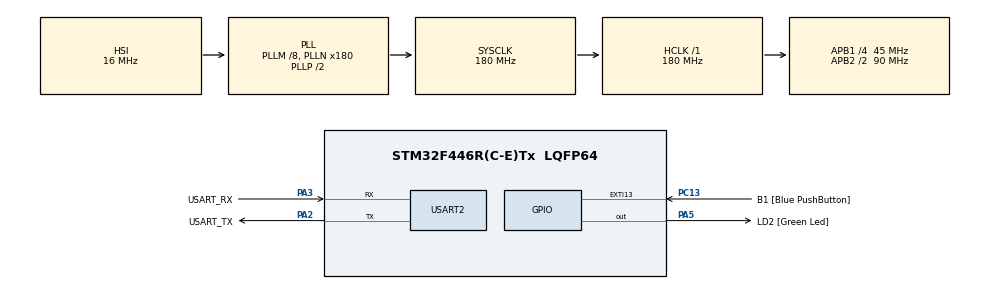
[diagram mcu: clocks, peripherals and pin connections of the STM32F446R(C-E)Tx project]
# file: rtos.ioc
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FREERTOS.Tasks01=defaultTask,24,128,StartDefaultTask,Default,NULL,Dynamic,NULL,NULL
FREERTOS.configUSE_NEWLIB_REENTRANT=0
Mcu.Family=STM32F4
Mcu.Name=STM32F446R(C-E)Tx
Mcu.Package=LQFP64
NVIC.PriorityGroup=NVIC_PRIORITYGROUP_4
NVIC.TIM6_DAC_IRQn=true\:15\:0\:false\:false\:true\:false\:false\:true\:true
NVIC.TimeBase=TIM6_DAC_IRQn
NVIC.TimeBaseIP=TIM6
PA13.GPIO_Label=TMS
PA13.Mode=Serial_Wire
PA13.Signal=SYS_JTMS-SWDIO
PA14.GPIO_Label=TCK
PA14.Mode=Serial_Wire
PA14.Signal=SYS_JTCK-SWCLK
PA2.GPIO_Label=USART_TX
PA2.Mode=Asynchronous
PA2.Signal=USART2_TX
PA3.GPIO_Label=USART_RX
PA3.Mode=Asynchronous
PA3.Signal=USART2_RX
PA5.GPIO_Label=LD2 [Green Led]
PA5.Signal=GPIO_Output
PB3.GPIO_Label=SWO
PB3.Signal=SYS_JTDO-SWO
PC13.GPIO_Label=B1 [Blue PushButton]
PC13.GPIO_ModeDefaultEXTI=GPIO_MODE_IT_FALLING
PC13.Signal=GPXTI13
PC14-OSC32_IN.Mode=LSE-External-Oscillator
PC14-OSC32_IN.Signal=RCC_OSC32_IN
PC15-OSC32_OUT.Mode=LSE-External-Oscillator
PC15-OSC32_OUT.Signal=RCC_OSC32_OUT
PH0-OSC_IN.Mode=HSE-External-Oscillator
PH0-OSC_IN.Signal=RCC_OSC_IN
PH1-OSC_OUT.Mode=HSE-External-Oscillator
PH1-OSC_OUT.Signal=RCC_OSC_OUT
ProjectManager.HeapSize=0x200
ProjectManager.StackSize=0x400
ProjectManager.TargetToolchain=STM32CubeIDE
RCC.48MHZClocksFreq_Value=84000000
RCC.AHBFreq_Value=180000000
RCC.APB1CLKDivider=RCC_HCLK_DIV4
RCC.APB1Freq_Value=45000000
RCC.APB1TimFreq_Value=90000000
RCC.APB2CLKDivider=RCC_HCLK_DIV2
RCC.APB2Freq_Value=90000000
RCC.APB2TimFreq_Value=180000000
RCC.CortexFreq_Value=180000000
RCC.FLatency-AdvancedSettings=FLASH_LATENCY_5
RCC.HCLKFreq_Value=180000000
RCC.HSE_VALUE=8000000
RCC.HSI_VALUE=16000000
RCC.PLLM=8
RCC.PLLN=180
RCC.SYSCLKFreq_VALUE=180000000
RCC.SYSCLKSource=RCC_SYSCLKSOURCE_PLLCLK
RCC.USBFreq_Value=180000000
RCC.VCOOutputFreq_Value=360000000
USART2.VirtualMode=VM_ASYNC
VP_FREERTOS_VS_CMSIS_V2.Mode=CMSIS_V2
VP_SYS_VS_tim6.Mode=TIM6
board=NUCLEO-F446RE

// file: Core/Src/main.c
/* USER CODE BEGIN Header */
/**
  ******************************************************************************
  * @file           : main.c
  * @brief          : Main program body
  ******************************************************************************
  * @attention
  *
  * Copyright (c) 2026 STMicroelectronics.
  * All rights reserved.
  *
  * This software is licensed under terms that can be found in the LICENSE file
  * in the root directory of this software component.
  * If no LICENSE file comes with this software, it is provided AS-IS.
  *
  ******************************************************************************
  */
/* USER CODE END Header */
#include "main.h"
#include "FreeRTOS.h"
#include "task.h"
#include "queue.h"
#include "stdio_ext.h"
#include "string.h"
#include "semphr.h"

UART_HandleTypeDef huart2;
static SemaphoreHandle_t xUartMutex = NULL;

void SystemClock_Config(void);
static void MX_GPIO_Init(void);
static void MX_USART2_UART_Init(void);

static QueueHandle_t xRxQueue = NULL;

static void uart_puts(const char *s)
{
	// If scheduler is not started mean not need for uart mutex
	if (xTaskGetSchedulerState() == taskSCHEDULER_NOT_STARTED)
	{
		HAL_UART_Transmit(&huart2, (const uint8_t*)s, strlen(s), HAL_MAX_DELAY);
	}
	else
	{
	// scheduler is started, lock via mutex, send the data and give mutex
		if(xSemaphoreTake(xUartMutex, portMAX_DELAY) == pdTRUE)
		{
			HAL_UART_Transmit(&huart2, (const uint8_t*)s, strlen(s), HAL_MAX_DELAY);
			xSemaphoreGive(xUartMutex);
		}
	}
}

/* Simple code to print using uart instead of printf*/

static void uart_print_u32(const char *ch, uint32_t value)
{
	char buffer[32];
	char temp[12];

	int i = 0, j = 0;

	// "ch" msg
	while(ch[i])
	{
		buffer[j++] = ch[i++];
	}

	// print the value
	if(value == 0)
	{
		buffer[j++] = '0'; // simple case
	}
	else // TODO: Need to revist the below logic
	{
		int k = 0;
		while (value > 0)
		{
			temp[k++] = '0' + (value % 10);
			value /= 10;
		}
		while (k > 0)
		{
			buffer[j++] = temp[--k];
		}
	}

	buffer[j++]='\r';
	buffer[j++]='\n';
	buffer[j] = 0;

	uart_puts(buffer);
}

/* A simple task for LED blink & heartbeat*/
static void task_led(void *pvParams)
{
	uart_puts("LED Task Started. Priority=1\r\n");
	//\n\r might give an empty line, so the standard is \r\n

	/* Add this temporarily — remove after debugging */
	    UBaseType_t wm = uxTaskGetStackHighWaterMark(NULL);
	    /* print wm using uart_print_u32 */
	    uart_print_u32("LED stack watermark=", wm);

	uint32_t count = 0;
	while(1)
	{
		HAL_GPIO_WritePin(LD2_GPIO_Port, LD2_Pin, GPIO_PIN_SET);
		/*Led ON, LD2 in pinout diagram in CUBE*/
		uart_puts("LED is ON\r\n");
		vTaskDelay(pdMS_TO_TICKS(500));
		/*always use ticks*/

		HAL_GPIO_WritePin(LD2_GPIO_Port, LD2_Pin, GPIO_PIN_RESET);
		/*LED off*/
		uart_puts("LED is off\r\n");
		vTaskDelay(pdMS_TO_TICKS(500));

		count++;
		uart_print_u32("LED cycle: ", count);
	}
}

/* A simple tcik counter*/
static void task_hearbeat(void *pvParams)
{
	 uart_puts("HB Task started. Priority=1\r\n");

	 while(1)
	 {
		 vTaskDelay(pdMS_TO_TICKS(2000));
		 uart_print_u32("HB tick=",xTaskGetTickCount());

		 // printing heap size
		 uart_print_u32("HB free_heap=", xPortGetFreeHeapSize());
	 }
}

/* A function to repricate the console characters*/
static void task_uart_rx(void *pvParams)
{
	uart_puts("RX Task started. Type characters\r\n");

	char ch;
	while(1)
	{
		// wait until a character is arrived in the queue
		if(xQueueReceive(xRxQueue, &ch, portMAX_DELAY) == pdPASS)
		{
			// form echo command with ch
			char echoCommand[8] = {'E', 'C', '>', ch, '\r', '\n', 0};
			uart_puts(echoCommand);

			if(ch == '\r')
			{
				uart_puts("Enter key is pressed\r\n");
			}
		}
	}
}

/*USART2 ISR -> this will replace any USART2_IRQHandler
 * Enable USART2 RXNE interrupt in MX_USART2_UART_Init*/
void USART2_IRQHandler(void)
{
	 if (USART2->SR & (1U << 5)) /* RXNE flag */
	 {
		 char c = (char)USART2->DR;                  /* clears RXNE */
		 BaseType_t xHigherPriorityTaskWoken  = pdFALSE; /*alawys to be initalized*/

		 xQueueSendFromISR(xRxQueue, &c, &xHigherPriorityTaskWoken);
		 portYIELD_FROM_ISR(xHigherPriorityTaskWoken);
	 }
}

void vApplicationStackOverflowHook(TaskHandle_t xTask, char *pcTaskName)
{
    (void)xTask;
    uart_puts("\r\n*** STACK OVERFLOW: ");
    uart_puts(pcTaskName);
    uart_puts(" ***\r\n");
    taskDISABLE_INTERRUPTS();
    for (;;);
}

void vApplicationMallocFailedHook(void)
{
	uart_puts("\r\n*** MALLOC FAILED — increase configTOTAL_HEAP_SIZE ***\r\n");
	taskDISABLE_INTERRUPTS();
	for (;;);
}
int main(void)
{

  /* MCU Configuration--------------------------------------------------------*/

  /* Reset of all peripherals, Initializes the Flash interface and the Systick. */
  HAL_Init();

  /* Configure the system clock */
  SystemClock_Config();
  // Verify: this should print 180000000

  /* Initialize all configured peripherals */
  MX_GPIO_Init();
  MX_USART2_UART_Init();

  /* Enable USART2 RXNE interrupt for the RX task */
  USART2->CR1 |= (1U << 5);                       /* RXNEIE bit */
  NVIC_SetPriority(USART2_IRQn, 5);               /* >= configLIBRARY_MAX_SYSCALL_INTERRUPT_PRIORITY */
  NVIC_EnableIRQ(USART2_IRQn);

  uart_puts("Starting\r\n");

  /* USER CODE BEGIN RTOS_QUEUES */
  xRxQueue = xQueueCreate(32, sizeof(char));
  if (xRxQueue == NULL) {
	  uart_puts("FATAL: queue create failed\r\n");
	  for (;;);
  }
  /* USER CODE END RTOS_QUEUES */

  /* Create tasks — check return values! */

  xUartMutex = xSemaphoreCreateMutex();
  if(xUartMutex == NULL)
  {
	  HAL_GPIO_WritePin(LD2_GPIO_Port, LD2_Pin, GPIO_PIN_SET);
	  for (;;);
  }

  uart_puts("Creating tasks\r\n");
  BaseType_t r1 = xTaskCreate(task_led,       "LED",  256, NULL, 1, NULL);
  BaseType_t r2 = xTaskCreate(task_hearbeat, "HB",   256, NULL, 1, NULL);
  BaseType_t r3 = xTaskCreate(task_uart_rx,   "RX",   256, NULL, 2, NULL);

  if (r1 != pdPASS || r2 != pdPASS || r3 != pdPASS)
  {
	  uart_puts("FATAL: xTaskCreate failed — heap too small\r\n");
	  for (;;);
  }
  else
  {
	  uart_puts("Tasks created sucessfully\r\n");
  }

  uart_puts("Tasks created. Starting scheduler...\r\n");
  vTaskStartScheduler();   /* Never returns if heap is sufficient */

  uart_puts("FATAL: scheduler returned — heap exhausted\r\n");
  for (;;);

}

void SystemClock_Config(void)
{
  RCC_OscInitTypeDef RCC_OscInitStruct = {0};
  RCC_ClkInitTypeDef RCC_ClkInitStruct = {0};

  /** Configure the main internal regulator output voltage
  */
  __HAL_RCC_PWR_CLK_ENABLE();
  __HAL_PWR_VOLTAGESCALING_CONFIG(PWR_REGULATOR_VOLTAGE_SCALE1);

  /** Initializes the RCC Oscillators according to the specified parameters
  * in the RCC_OscInitTypeDef structure.
  */
  RCC_OscInitStruct.OscillatorType = RCC_OSCILLATORTYPE_HSI;
  RCC_OscInitStruct.HSIState = RCC_HSI_ON;
  RCC_OscInitStruct.HSICalibrationValue = RCC_HSICALIBRATION_DEFAULT;
  RCC_OscInitStruct.PLL.PLLState = RCC_PLL_ON;
  RCC_OscInitStruct.PLL.PLLSource = RCC_PLLSOURCE_HSI;
  RCC_OscInitStruct.PLL.PLLM = 8;
  RCC_OscInitStruct.PLL.PLLN = 180;
  RCC_OscInitStruct.PLL.PLLP = RCC_PLLP_DIV2;
  RCC_OscInitStruct.PLL.PLLQ = 4;
  RCC_OscInitStruct.PLL.PLLR = 2;
  if (HAL_RCC_OscConfig(&RCC_OscInitStruct) != HAL_OK)
  {
    Error_Handler();
  }

  /** Initializes the CPU, AHB and APB buses clocks
  */
  RCC_ClkInitStruct.ClockType = RCC_CLOCKTYPE_HCLK|RCC_CLOCKTYPE_SYSCLK
                              |RCC_CLOCKTYPE_PCLK1|RCC_CLOCKTYPE_PCLK2;
  RCC_ClkInitStruct.SYSCLKSource = RCC_SYSCLKSOURCE_PLLCLK;
  RCC_ClkInitStruct.AHBCLKDivider = RCC_SYSCLK_DIV1;
  RCC_ClkInitStruct.APB1CLKDivider = RCC_HCLK_DIV4;
  RCC_ClkInitStruct.APB2CLKDivider = RCC_HCLK_DIV2;

  if (HAL_RCC_ClockConfig(&RCC_ClkInitStruct, FLASH_LATENCY_5) != HAL_OK)
  {
    Error_Handler();
  }
}

static void MX_USART2_UART_Init(void)
{

  huart2.Instance = USART2;
  huart2.Init.BaudRate = 115200;
  huart2.Init.WordLength = UART_WORDLENGTH_8B;
  huart2.Init.StopBits = UART_STOPBITS_1;
  huart2.Init.Parity = UART_PARITY_NONE;
  huart2.Init.Mode = UART_MODE_TX_RX;
  huart2.Init.HwFlowCtl = UART_HWCONTROL_NONE;
  huart2.Init.OverSampling = UART_OVERSAMPLING_16;
  if (HAL_UART_Init(&huart2) != HAL_OK)
  {
    Error_Handler();
  }

}

static void MX_GPIO_Init(void)
{
  GPIO_InitTypeDef GPIO_InitStruct = {0};

  /* GPIO Ports Clock Enable */
  __HAL_RCC_GPIOC_CLK_ENABLE();
  __HAL_RCC_GPIOH_CLK_ENABLE();
  __HAL_RCC_GPIOA_CLK_ENABLE();
  __HAL_RCC_GPIOB_CLK_ENABLE();

  /*Configure GPIO pin Output Level */
  HAL_GPIO_WritePin(LD2_GPIO_Port, LD2_Pin, GPIO_PIN_RESET);

  /*Configure GPIO pin : B1_Pin */
  GPIO_InitStruct.Pin = B1_Pin;
  GPIO_InitStruct.Mode = GPIO_MODE_INPUT;
  GPIO_InitStruct.Pull = GPIO_NOPULL;
  HAL_GPIO_Init(B1_GPIO_Port, &GPIO_InitStruct);

  /*Configure GPIO pin : LD2_Pin */
  GPIO_InitStruct.Pin = LD2_Pin;
  GPIO_InitStruct.Mode = GPIO_MODE_OUTPUT_PP;
  GPIO_InitStruct.Pull = GPIO_NOPULL;
  GPIO_InitStruct.Speed = GPIO_SPEED_FREQ_LOW;
  HAL_GPIO_Init(LD2_GPIO_Port, &GPIO_InitStruct);

}

void HAL_TIM_PeriodElapsedCallback(TIM_HandleTypeDef *htim)
{
  if (htim->Instance == TIM6)
  {
    HAL_IncTick();
  }
}

void Error_Handler(void)
{
  __disable_irq();
  while (1)
  {
  }
}
